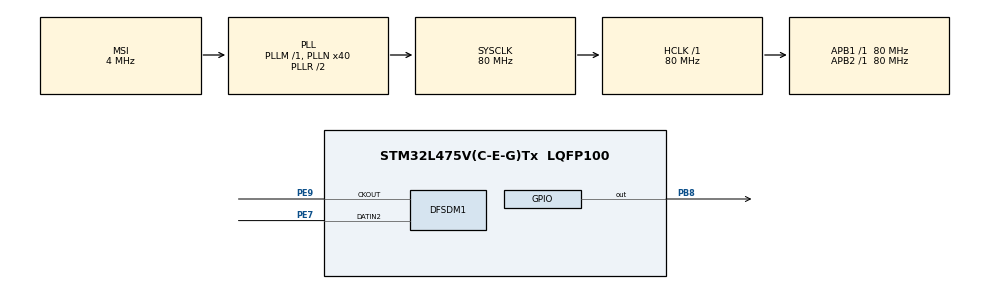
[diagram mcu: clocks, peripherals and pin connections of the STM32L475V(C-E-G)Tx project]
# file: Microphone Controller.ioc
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DFSDM1.Divider=40
DFSDM1.DmaMode_reg_FIL0=ENABLE
DFSDM1.FastMode_reg_FIL0=ENABLE
DFSDM1.Filter_regChannel_FIL0=DFSDM_CHANNEL_2
DFSDM1.Fosr_FIL0=250
DFSDM1.SincOrder_FIL0=DFSDM_FILTER_SINC3_ORDER
Dma.DFSDM1_FLT0.0.Direction=DMA_PERIPH_TO_MEMORY
Dma.DFSDM1_FLT0.0.Instance=DMA1_Channel4
Dma.DFSDM1_FLT0.0.MemDataAlignment=DMA_MDATAALIGN_WORD
Dma.DFSDM1_FLT0.0.MemInc=DMA_MINC_ENABLE
Dma.DFSDM1_FLT0.0.Mode=DMA_CIRCULAR
Dma.DFSDM1_FLT0.0.PeriphDataAlignment=DMA_PDATAALIGN_WORD
Dma.DFSDM1_FLT0.0.PeriphInc=DMA_PINC_DISABLE
Dma.DFSDM1_FLT0.0.Priority=DMA_PRIORITY_LOW
Dma.Request0=DFSDM1_FLT0
Mcu.Family=STM32L4
Mcu.Name=STM32L475V(C-E-G)Tx
Mcu.Package=LQFP100
NVIC.DMA1_Channel4_IRQn=true\:0\:0\:false\:false\:true\:false\:true\:true
NVIC.PriorityGroup=NVIC_PRIORITYGROUP_4
NVIC.TIM3_IRQn=true\:0\:0\:false\:false\:true\:true\:true\:true
PB8.Signal=GPIO_Output
PE7.Signal=S_DATAIN2DFSDM1
PE9.Signal=S_CKOUTDFSDM1
ProjectManager.HeapSize=0x200
ProjectManager.StackSize=0x400
ProjectManager.TargetToolchain=STM32CubeIDE
RCC.AHBFreq_Value=80000000
RCC.APB1Freq_Value=80000000
RCC.APB1TimFreq_Value=80000000
RCC.APB2Freq_Value=80000000
RCC.APB2TimFreq_Value=80000000
RCC.CortexFreq_Value=80000000
RCC.HCLKFreq_Value=80000000
RCC.HSE_VALUE=8000000
RCC.HSI_VALUE=16000000
RCC.LSE_VALUE=32768
RCC.MSI_VALUE=4000000
RCC.PLLN=40
RCC.SYSCLKFreq_VALUE=80000000
RCC.SYSCLKSource=RCC_SYSCLKSOURCE_PLLCLK
RCC.VCOOutputFreq_Value=160000000
SH.S_CKOUTDFSDM1.0=DFSDM1_CKOUT,PDM_SPI_input_from_ch2_and_internal_clock
SH.S_DATAIN2DFSDM1.0=DFSDM1_DATIN2,PDM_SPI_input_from_ch2_and_internal_clock
TIM3.AutoReloadPreload=TIM_AUTORELOAD_PRELOAD_DISABLE
TIM3.Period=7999
TIM3.Prescaler=999
VP_TIM3_VS_ClockSourceINT.Mode=Internal
board=custom

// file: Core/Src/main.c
/* USER CODE BEGIN Header */
/**
  ******************************************************************************
  * @file           : main.c
  * @brief          : Main program body
  ******************************************************************************
  * @attention
  *
  * Copyright (c) 2025 STMicroelectronics.
  * All rights reserved.
  *
  * This software is licensed under terms that can be found in the LICENSE file
  * in the root directory of this software component.
  * If no LICENSE file comes with this software, it is provided AS-IS.
  *
  ******************************************************************************
  */
/* USER CODE END Header */
#include "main.h"
#include "stm32l4xx_it.h"

DFSDM_Filter_HandleTypeDef hdfsdm1_filter0;
DFSDM_Channel_HandleTypeDef hdfsdm1_channel2;
DMA_HandleTypeDef hdma_dfsdm1_flt0;

TIM_HandleTypeDef htim3;

/* USER CODE BEGIN PV */
#define BUFFER_LEN	1024
#define ABS(x) ((x) > 0 ? (x) : -(x))
int32_t raw_pcm_buffer[BUFFER_LEN];
int32_t prev_mean = 0; //mean of the previous reading chunk
uint8_t DmaRecHalfBuffCplt = 0;
uint8_t DmaRecBuffCplt = 0;
uint64_t start_time = 0;

/* USER CODE END PV */

void SystemClock_Config(void);
static void MX_GPIO_Init(void);
static void MX_DMA_Init(void);
static void MX_DFSDM1_Init(void);
static void MX_TIM3_Init(void);

/* USER CODE BEGIN 0 */

void send_signal(){
	int status = HAL_GPIO_ReadPin(GPIOB, GPIO_PIN_8);
	if (status == 0){
		HAL_GPIO_WritePin(GPIOB, GPIO_PIN_8, GPIO_PIN_SET);
		__HAL_TIM_SET_AUTORELOAD(&htim3, 10000);
		__HAL_TIM_SET_COUNTER(&htim3, 0);
		HAL_TIM_Base_Start_IT(&htim3);
	}
}

/*
 * This function takes in the pcm values and compares them to the previous values to determine if a spike in the
 * readings has occured.
 */
void process_audio(int32_t * pcm_buffer) {
	int64_t sum = 0;
	int send_one = 0;
	for (int i = 0; i < BUFFER_LEN/2; i++){
		int32_t val = (pcm_buffer[i] >> 8);
		//80000 is chosen based on testing since there will always be some variance.
		// We could also calculate variance but that would take a lot longer.
		if (val - prev_mean > 80000 && send_one == 0){
			send_one = 1;
			send_signal(); // send a high signal to the controller.
		}
		sum+=val;
	}
	prev_mean = sum/(BUFFER_LEN/2);
}

/* USER CODE END 0 */

int main(void) {

	/* MCU Configuration--------------------------------------------------------*/

	/* Reset of all peripherals, Initializes the Flash interface and the Systick. */
	HAL_Init();

	/* Configure the system clock */
	SystemClock_Config();

	/* Initialize all configured peripherals */
	MX_GPIO_Init();
	MX_DMA_Init();
	MX_DFSDM1_Init();
	MX_TIM3_Init();
	/* USER CODE BEGIN 2 */
	//This sets us up and starts reading from the DMA to a buffer.
	HAL_DFSDM_FilterRegularStart_DMA(&hdfsdm1_filter0, raw_pcm_buffer, BUFFER_LEN);
	/* USER CODE END 2 */

	/* Infinite loop */
	/* USER CODE BEGIN WHILE */
	int warmup = 0; // a warmup for the microphone in case of any funky data during the first couple of reads.
	while (1) {
		if (DmaRecHalfBuffCplt == 1){
			if (warmup < 10){
				warmup++; //skip this read
			}
			else{
				process_audio(&raw_pcm_buffer[0]);
			}
			DmaRecHalfBuffCplt = 0;
		}
		if (DmaRecBuffCplt == 1){
			if (warmup < 10){
			//right before we start reading for real, we want a previous baseline mean to compare spikes to
				if (warmup == 9){
					int64_t sum = 0;
					for (int i = 0; i < BUFFER_LEN; i++){
						sum+=raw_pcm_buffer[i] >> 8;
					}
					prev_mean = sum/BUFFER_LEN;
				}
				warmup++; //skip this read
			}
			else{
				process_audio(&raw_pcm_buffer[BUFFER_LEN/2]);
			}
			DmaRecBuffCplt = 0;
		}
		/* USER CODE END 3 */
	}
}

void SystemClock_Config(void)
{
  RCC_OscInitTypeDef RCC_OscInitStruct = {0};
  RCC_ClkInitTypeDef RCC_ClkInitStruct = {0};

  /** Configure the main internal regulator output voltage
  */
  if (HAL_PWREx_ControlVoltageScaling(PWR_REGULATOR_VOLTAGE_SCALE1) != HAL_OK)
  {
    Error_Handler();
  }

  /** Initializes the RCC Oscillators according to the specified parameters
  * in the RCC_OscInitTypeDef structure.
  */
  RCC_OscInitStruct.OscillatorType = RCC_OSCILLATORTYPE_MSI;
  RCC_OscInitStruct.MSIState = RCC_MSI_ON;
  RCC_OscInitStruct.MSICalibrationValue = 0;
  RCC_OscInitStruct.MSIClockRange = RCC_MSIRANGE_6;
  RCC_OscInitStruct.PLL.PLLState = RCC_PLL_ON;
  RCC_OscInitStruct.PLL.PLLSource = RCC_PLLSOURCE_MSI;
  RCC_OscInitStruct.PLL.PLLM = 1;
  RCC_OscInitStruct.PLL.PLLN = 40;
  RCC_OscInitStruct.PLL.PLLP = RCC_PLLP_DIV7;
  RCC_OscInitStruct.PLL.PLLQ = RCC_PLLQ_DIV2;
  RCC_OscInitStruct.PLL.PLLR = RCC_PLLR_DIV2;
  if (HAL_RCC_OscConfig(&RCC_OscInitStruct) != HAL_OK)
  {
    Error_Handler();
  }

  /** Initializes the CPU, AHB and APB buses clocks
  */
  RCC_ClkInitStruct.ClockType = RCC_CLOCKTYPE_HCLK|RCC_CLOCKTYPE_SYSCLK
                              |RCC_CLOCKTYPE_PCLK1|RCC_CLOCKTYPE_PCLK2;
  RCC_ClkInitStruct.SYSCLKSource = RCC_SYSCLKSOURCE_PLLCLK;
  RCC_ClkInitStruct.AHBCLKDivider = RCC_SYSCLK_DIV1;
  RCC_ClkInitStruct.APB1CLKDivider = RCC_HCLK_DIV1;
  RCC_ClkInitStruct.APB2CLKDivider = RCC_HCLK_DIV1;

  if (HAL_RCC_ClockConfig(&RCC_ClkInitStruct, FLASH_LATENCY_4) != HAL_OK)
  {
    Error_Handler();
  }
}

static void MX_DFSDM1_Init(void)
{

  hdfsdm1_filter0.Instance = DFSDM1_Filter0;
  hdfsdm1_filter0.Init.RegularParam.Trigger = DFSDM_FILTER_SW_TRIGGER;
  hdfsdm1_filter0.Init.RegularParam.FastMode = ENABLE;
  hdfsdm1_filter0.Init.RegularParam.DmaMode = ENABLE;
  hdfsdm1_filter0.Init.FilterParam.SincOrder = DFSDM_FILTER_SINC3_ORDER;
  hdfsdm1_filter0.Init.FilterParam.Oversampling = 250;
  hdfsdm1_filter0.Init.FilterParam.IntOversampling = 1;
  if (HAL_DFSDM_FilterInit(&hdfsdm1_filter0) != HAL_OK)
  {
    Error_Handler();
  }
  hdfsdm1_channel2.Instance = DFSDM1_Channel2;
  hdfsdm1_channel2.Init.OutputClock.Activation = ENABLE;
  hdfsdm1_channel2.Init.OutputClock.Selection = DFSDM_CHANNEL_OUTPUT_CLOCK_SYSTEM;
  hdfsdm1_channel2.Init.OutputClock.Divider = 40;
  hdfsdm1_channel2.Init.Input.Multiplexer = DFSDM_CHANNEL_EXTERNAL_INPUTS;
  hdfsdm1_channel2.Init.Input.DataPacking = DFSDM_CHANNEL_STANDARD_MODE;
  hdfsdm1_channel2.Init.Input.Pins = DFSDM_CHANNEL_SAME_CHANNEL_PINS;
  hdfsdm1_channel2.Init.SerialInterface.Type = DFSDM_CHANNEL_SPI_RISING;
  hdfsdm1_channel2.Init.SerialInterface.SpiClock = DFSDM_CHANNEL_SPI_CLOCK_INTERNAL;
  hdfsdm1_channel2.Init.Awd.FilterOrder = DFSDM_CHANNEL_FASTSINC_ORDER;
  hdfsdm1_channel2.Init.Awd.Oversampling = 1;
  hdfsdm1_channel2.Init.Offset = 0;
  hdfsdm1_channel2.Init.RightBitShift = 0x00;
  if (HAL_DFSDM_ChannelInit(&hdfsdm1_channel2) != HAL_OK)
  {
    Error_Handler();
  }
  if (HAL_DFSDM_FilterConfigRegChannel(&hdfsdm1_filter0, DFSDM_CHANNEL_2, DFSDM_CONTINUOUS_CONV_ON) != HAL_OK)
  {
    Error_Handler();
  }

}

static void MX_TIM3_Init(void)
{

  TIM_ClockConfigTypeDef sClockSourceConfig = {0};
  TIM_MasterConfigTypeDef sMasterConfig = {0};

  htim3.Instance = TIM3;
  htim3.Init.Prescaler = 999;
  htim3.Init.CounterMode = TIM_COUNTERMODE_UP;
  htim3.Init.Period = 7999;
  htim3.Init.ClockDivision = TIM_CLOCKDIVISION_DIV1;
  htim3.Init.AutoReloadPreload = TIM_AUTORELOAD_PRELOAD_DISABLE;
  if (HAL_TIM_Base_Init(&htim3) != HAL_OK)
  {
    Error_Handler();
  }
  sClockSourceConfig.ClockSource = TIM_CLOCKSOURCE_INTERNAL;
  if (HAL_TIM_ConfigClockSource(&htim3, &sClockSourceConfig) != HAL_OK)
  {
    Error_Handler();
  }
  sMasterConfig.MasterOutputTrigger = TIM_TRGO_RESET;
  sMasterConfig.MasterSlaveMode = TIM_MASTERSLAVEMODE_DISABLE;
  if (HAL_TIMEx_MasterConfigSynchronization(&htim3, &sMasterConfig) != HAL_OK)
  {
    Error_Handler();
  }

}

static void MX_DMA_Init(void)
{

  /* DMA controller clock enable */
  __HAL_RCC_DMA1_CLK_ENABLE();

  /* DMA interrupt init */
  /* DMA1_Channel4_IRQn interrupt configuration */
  HAL_NVIC_SetPriority(DMA1_Channel4_IRQn, 0, 0);
  HAL_NVIC_EnableIRQ(DMA1_Channel4_IRQn);

}

static void MX_GPIO_Init(void)
{
  GPIO_InitTypeDef GPIO_InitStruct = {0};

  /* GPIO Ports Clock Enable */
  __HAL_RCC_GPIOE_CLK_ENABLE();
  __HAL_RCC_GPIOB_CLK_ENABLE();

  /*Configure GPIO pin Output Level */
  HAL_GPIO_WritePin(GPIOB, GPIO_PIN_8, GPIO_PIN_RESET);

  /*Configure GPIO pin : PB8 */
  GPIO_InitStruct.Pin = GPIO_PIN_8;
  GPIO_InitStruct.Mode = GPIO_MODE_OUTPUT_PP;
  GPIO_InitStruct.Pull = GPIO_NOPULL;
  GPIO_InitStruct.Speed = GPIO_SPEED_FREQ_LOW;
  HAL_GPIO_Init(GPIOB, &GPIO_InitStruct);

}

/* USER CODE BEGIN 4 */
//call backs to let us know if the buffer was half full or fully full
void HAL_DFSDM_FilterRegConvHalfCpltCallback(DFSDM_Filter_HandleTypeDef *hdfsdm_filter){
	DmaRecHalfBuffCplt=1;
}
void HAL_DFSDM_FilterRegConvCpltCallback(DFSDM_Filter_HandleTypeDef *hdfsdm_filter){
	DmaRecBuffCplt=1;
}

void HAL_TIM_PeriodElapsedCallback(TIM_HandleTypeDef *htim){
	if (htim->Instance == TIM3){
		HAL_GPIO_WritePin(GPIOB, GPIO_PIN_8, GPIO_PIN_RESET);
		HAL_TIM_Base_Stop_IT(&htim3);
	}
}

/* USER CODE END 4 */

void Error_Handler(void)
{
  __disable_irq();
  while (1) {
  }
}
